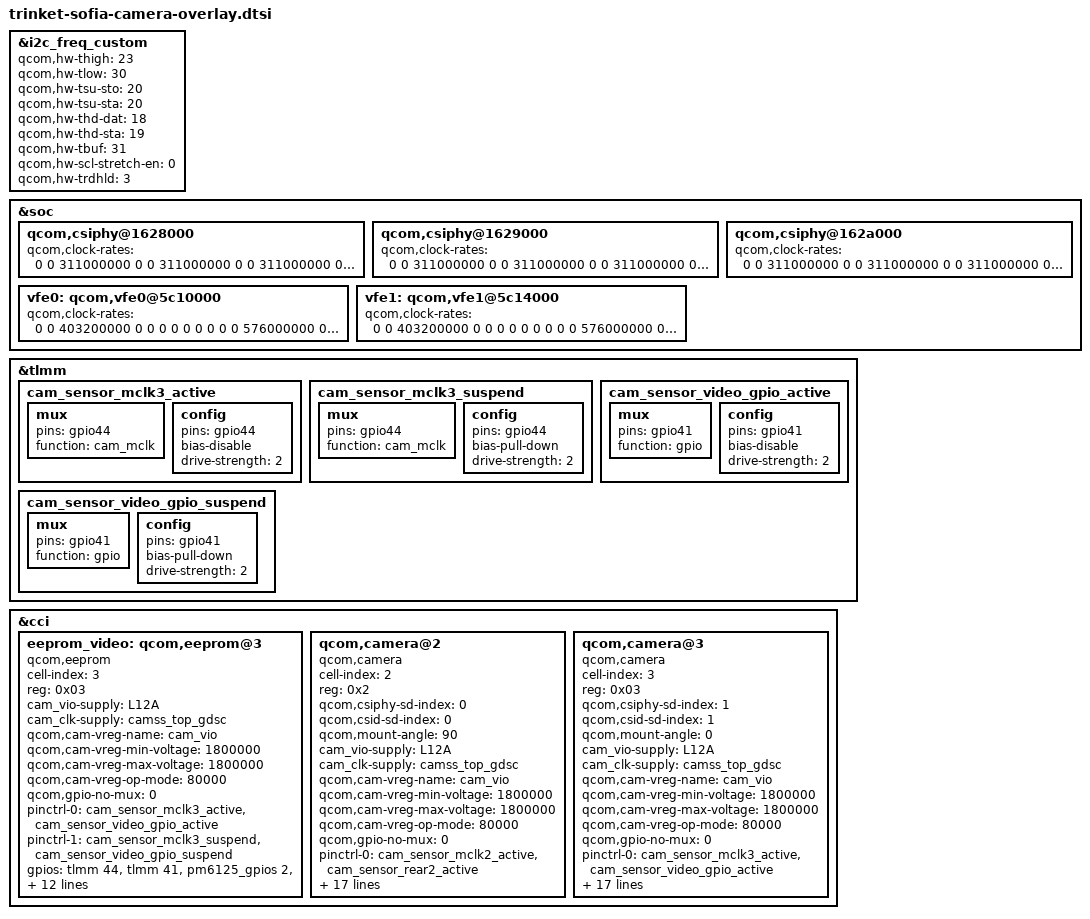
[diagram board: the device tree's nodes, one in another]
/*
 * Copyright (c) 2019, The Linux Foundation. All rights reserved.
 *
 * This program is free software; you can redistribute it and/or modify
 * it under the terms of the GNU General Public License version 2 and
 * only version 2 as published by the Free Software Foundation.
 *
 * This program is distributed in the hope that it will be useful,
 * but WITHOUT ANY WARRANTY; without even the implied warranty of
 * MERCHANTABILITY or FITNESS FOR A PARTICULAR PURPOSE.  See the
 * GNU General Public License for more details.
 */
&i2c_freq_custom {
	qcom,hw-thigh = <23>;
	qcom,hw-tlow = <30>;
	qcom,hw-tsu-sto = <20>;
	qcom,hw-tsu-sta = <20>;
	qcom,hw-thd-dat = <18>;
	qcom,hw-thd-sta = <19>;
	qcom,hw-tbuf = <31>;
	qcom,hw-scl-stretch-en = <0>;
	qcom,hw-trdhld = <3>;
};

&soc {
	qcom,csiphy@1628000 {
		qcom,clock-rates = <0 0 311000000 0 0 311000000 0
			0 311000000 0 0>;
	};

	qcom,csiphy@1629000 {
		qcom,clock-rates = <0 0 311000000 0 0 311000000 0
			0 311000000 0 0>;
	};

	qcom,csiphy@162a000 {
		qcom,clock-rates = <0 0 311000000 0 0 311000000 0
			0 311000000 0 0>;

	};

	vfe0: qcom,vfe0@5c10000 {
		qcom,clock-rates = <0 0 403200000 0 0 0 0 0 0 0
					0 0 576000000 0 0 0 0 0 0 0
					0 0 576000000 0 0 0 0 0 0 0>;
	};

	vfe1: qcom,vfe1@5c14000 {
		qcom,clock-rates = <0 0 403200000 0 0 0 0 0 0 0
					0 0 576000000 0 0 0 0 0 0 0
					0 0 576000000 0 0 0 0 0 0 0>;
	};
};

&tlmm {
	cam_sensor_mclk3_active: cam_sensor_mclk3_active {
		/* MCLK3 */
		mux {
			pins = "gpio44";
			function = "cam_mclk";
		};

		config {
			pins = "gpio44";
			bias-disable; /* No PULL */
			drive-strength = <2>; /* 2 MA */
		};
	};

	cam_sensor_mclk3_suspend: cam_sensor_mclk3_suspend {
		/* MCLK3 */
		mux {
			pins = "gpio44";
			function = "cam_mclk";
		};

		config {
			pins = "gpio44";
			bias-pull-down; /* PULL DOWN */
			drive-strength = <2>; /* 2 MA */
		};
	};
	cam_sensor_video_gpio_active: cam_sensor_video_gpio_active {
		/* RESET */
		mux {
			pins = "gpio41";
			function = "gpio";
		};

		config {
			pins = "gpio41";
			bias-disable; /* No PULL */
			drive-strength = <2>; /* 2 MA */
		};
	};

	cam_sensor_video_gpio_suspend: cam_sensor_video_gpio_suspend {
		/* RESET */
		mux {
			pins = "gpio41";
			function = "gpio";
		};

		config {
			pins = "gpio41";
			bias-pull-down; /* PULL DOWN */
			drive-strength = <2>; /* 2 MA */
		};
	};
};

&cci {
	eeprom_video: qcom,eeprom@3 {
		cell-index = <3>;
		compatible = "qcom,eeprom";
		reg = <0x03>;
		cam_vio-supply = <&L12A>;
		cam_clk-supply = <&camss_top_gdsc>;
		qcom,cam-vreg-name = "cam_vio";
		qcom,cam-vreg-min-voltage = <1800000>;
		qcom,cam-vreg-max-voltage = <1800000>;
		qcom,cam-vreg-op-mode = <80000>;
		qcom,gpio-no-mux = <0>;
		pinctrl-names = "cam_default", "cam_suspend";
		pinctrl-0 = <&cam_sensor_mclk3_active
				&cam_sensor_video_gpio_active>;
		pinctrl-1 = <&cam_sensor_mclk3_suspend
				&cam_sensor_video_gpio_suspend>;
		gpios = <&tlmm 44 0>,
			<&tlmm 41 0>,
			<&pm6125_gpios 2 0>,
			<&pm6125_gpios 8 0>;
		qcom,gpio-reset = <1>;
		qcom,gpio-vana = <2>;
		qcom,gpio-vdig = <3>;
		qcom,gpio-req-tbl-num = <0 1 2 3>;
		qcom,gpio-req-tbl-flags = <1 0 0 0>;
		qcom,gpio-req-tbl-label = "CAM_V_MCLK",
					  "CAM_V_RESET",
					  "CAM_V_AVDD",
					  "CAM_V_DVDD";
		qcom,cci-master = <0>;
		status = "ok";
		clocks = <&clock_gcc GCC_CAMSS_MCLK3_CLK_SRC>,
				<&clock_gcc GCC_CAMSS_MCLK3_CLK>;
		clock-names = "cam_src_clk", "cam_clk";
		qcom,clock-rates = <24000000 0>;
	};

	qcom,camera@2 {
		cell-index = <2>;
		compatible = "qcom,camera";
		reg = <0x2>;
		qcom,csiphy-sd-index = <0>;
		qcom,csid-sd-index = <0>;
		qcom,mount-angle = <90>;
		cam_vio-supply = <&L12A>;
		cam_clk-supply = <&camss_top_gdsc>;
		qcom,cam-vreg-name = "cam_vio";
		qcom,cam-vreg-min-voltage = <1800000>;
		qcom,cam-vreg-max-voltage = <1800000>;
		qcom,cam-vreg-op-mode = <80000>;
		qcom,gpio-no-mux = <0>;
		pinctrl-names = "cam_default", "cam_suspend";
		pinctrl-0 = <&cam_sensor_mclk2_active
				&cam_sensor_rear2_active>;
		pinctrl-1 = <&cam_sensor_mclk2_suspend
				&cam_sensor_rear2_suspend>;
		gpios = <&tlmm 36 0>,
			<&tlmm 46 0>,
			<&pm6125_gpios 2 0>,
			<&pm6125_gpios 9 0>;
		qcom,gpio-reset = <1>;
		qcom,gpio-vana = <2>;
		qcom,gpio-vio = <3>;
		qcom,gpio-req-tbl-num = <0 1 2 3>;
		qcom,gpio-req-tbl-flags = <1 0 0 0>;
		qcom,gpio-req-tbl-label = "CAM_S_MCLK",
					  "CAM_S_RESET",
					  "CAM_S_AVDD",
					  "CAM_S_VIO";
		qcom,sensor-position = <0>;
		qcom,sensor-mode = <0>;
		qcom,cci-master = <1>;
		status = "ok";
		clocks = <&clock_gcc GCC_CAMSS_MCLK2_CLK_SRC>,
				<&clock_gcc GCC_CAMSS_MCLK2_CLK>;
		clock-names = "cam_src_clk", "cam_clk";
		qcom,clock-rates = <24000000 0>;
	};

	qcom,camera@3 {
		cell-index = <3>;
		compatible = "qcom,camera";
		reg = <0x03>;
		qcom,csiphy-sd-index = <1>;
		qcom,csid-sd-index = <1>;
		qcom,mount-angle = <0>;
		cam_vio-supply = <&L12A>;
		cam_clk-supply = <&camss_top_gdsc>;
		qcom,cam-vreg-name = "cam_vio";
		qcom,cam-vreg-min-voltage = <1800000>;
		qcom,cam-vreg-max-voltage = <1800000>;
		qcom,cam-vreg-op-mode = <80000>;
		qcom,gpio-no-mux = <0>;
		pinctrl-names = "cam_default", "cam_suspend";
		pinctrl-0 = <&cam_sensor_mclk3_active
				&cam_sensor_video_gpio_active>;
		pinctrl-1 = <&cam_sensor_mclk3_suspend
				&cam_sensor_video_gpio_suspend>;
		gpios = <&tlmm 44 0>,
			<&tlmm 41 0>,
			<&pm6125_gpios 2 0>,
			<&pm6125_gpios 8 0>;
		qcom,gpio-reset = <1>;
		qcom,gpio-vana = <2>;
		qcom,gpio-vdig = <3>;
		qcom,gpio-req-tbl-num = <0 1 2 3>;
		qcom,gpio-req-tbl-flags = <1 0 0 0>;
		qcom,gpio-req-tbl-label = "CAM_V_MCLK",
					  "CAM_V_RESET",
					  "CAM_V_AVDD",
					  "CAM_V_DVDD";
		qcom,sensor-position = <0>;
		qcom,sensor-mode = <0>;
		qcom,cci-master = <0>;
		status = "ok";
		clocks = <&clock_gcc GCC_CAMSS_MCLK3_CLK_SRC>,
				<&clock_gcc GCC_CAMSS_MCLK3_CLK>;
		clock-names = "cam_src_clk", "cam_clk";
		qcom,clock-rates = <24000000 0>;
	};
};

